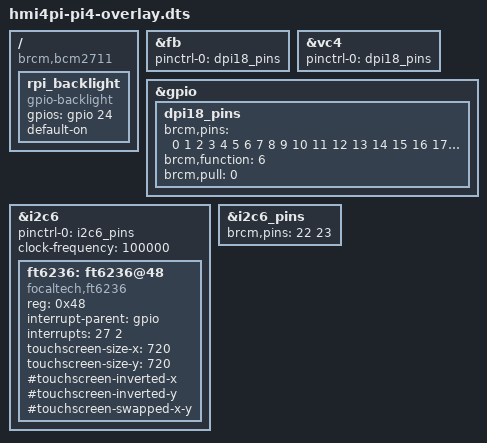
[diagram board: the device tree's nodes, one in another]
/*
 * Device Tree overlay for MakerLAB TFT 4.0" capacitive touch screen
 *
 */

/dts-v1/;
/plugin/;
/ {
	compatible = "brcm,bcm2711";

	fragment@0 {
		target = <&fb>;
		__overlay__ {
			pinctrl-names = "default";
			pinctrl-0 = <&dpi18_pins>;
		};
	};

	fragment@1 {
		target = <&vc4>;
		__overlay__ {
			pinctrl-names = "default";
			pinctrl-0 = <&dpi18_pins>;
		};
	};

	fragment@2 {
		target = <&gpio>;
		__overlay__ {
			dpi18_pins: dpi18_pins {
				brcm,pins = <0 1 2 3 4 5 6 7 8 9 10 11
					     12 13 14 15 16 17 18 19 20
					     21>;
				brcm,function = <6>; /* alt2 */
				brcm,pull = <0>; /* no pull */
			};
		};
	};

	fragment@3 {
		target-path = "/";
		__overlay__ {
			rpi_backlight: rpi_backlight {
				compatible = "gpio-backlight";
				gpios = <&gpio 24 0>;
				default-on;
			};
		};
	};

	fragment@4 {
		target = <&i2c6>;
		frag0: __overlay__ {
			status = "okay";
			pinctrl-names = "default";
			pinctrl-0 = <&i2c6_pins>;
			clock-frequency = <100000>;
		};
	};

	fragment@5 {
		target = <&i2c6_pins>;
		__overlay__ {
			brcm,pins = <22 23>;
		};
	};
	
	fragment@6 {
		target = <&i2c6>;
		__overlay__ {
			/* needed to avoid dtc warning */
			#address-cells = <1>;
			#size-cells = <0>;

                        ft6236: ft6236@48 {
                                compatible = "focaltech,ft6236";
                                reg = <0x48>;

                                interrupt-parent = <&gpio>;
                                interrupts = <27 2>;
                                touchscreen-size-x = <720>;
                                touchscreen-size-y = <720>;
				#touchscreen-inverted-x;
				#touchscreen-inverted-y;
				#touchscreen-swapped-x-y;
			};
		};
	};

	__overrides__ {
                touch-sizex = <&ft6236>,"touchscreen-size-x?";
                touch-sizey = <&ft6236>,"touchscreen-size-y?";
                touch-invx  = <&ft6236>,"touchscreen-inverted-x?";
                touch-invy  = <&ft6236>,"touchscreen-inverted-y?";
                touch-swapxy = <&ft6236>,"touchscreen-swapped-x-y?";
	};
};
